# LPC11D14 register map
File version: 4
CPU: 
Registers are 32-bit, read-write, reset 0x0 unless marked. A register's access mark holds for its fields unless they carry their own. Offsets are from the block's base; [hi:lo] are bit positions; {n}, {i} and the like mark numbered series.

## SYSCON — System configuration
Base 0x40048000
0x00 SYSMEMREMAP reset 0x2 — System memory remap
  [1:0] MAP
    0=BOOT_LOADER_MODE_IN (Boot Loader Mode. Interrupt vectors are re-mapped to Boot ROM.); 1=USER_RAM_MODE_INTER (User RAM Mode. Interrupt vectors are re-mapped to Static RAM.); 2=USER_FLASH_MODE_INT (User Flash Mode. Interrupt vectors are not re-mapped and reside in Flash.)
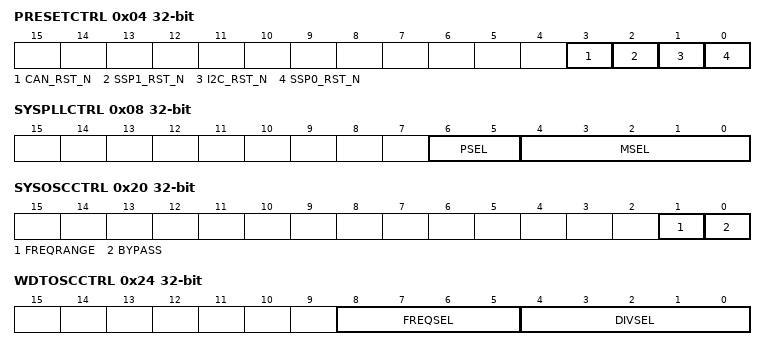
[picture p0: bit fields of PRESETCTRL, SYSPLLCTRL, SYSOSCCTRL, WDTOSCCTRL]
0x04 PRESETCTRL — Peripheral reset control
  [3] CAN_RST_N — C_CAN reset control. See Section 3.1 for part specific details.
    0=RESETS_THE_C_CAN_PER (Resets the C_CAN peripheral.); 1=C_CAN_RESET_DE_ASSER (C_CAN reset de-asserted.)
  [2] SSP1_RST_N — SPI1 reset control
    0=RESETS_THE_SPI1_PERI (Resets the SPI1 peripheral.); 1=SPI1_RESET_DE_ASSERT (SPI1 reset de-asserted.)
  [1] I2C_RST_N — I2C reset control
    0=RESETS_THE_I2C_PERIP (Resets the I2C peripheral.); 1=I2C_RESET_DE_ASSERTE (I2C reset de-asserted.)
  [0] SSP0_RST_N — SPI0 reset control
    0=RESETS_THE_SPI0_PERI (Resets the SPI0 peripheral.); 1=SPI0_RESET_DE_ASSERT (SPI0 reset de-asserted.)
0x08 SYSPLLCTRL — System PLL control
  [6:5] PSEL — Post divider ratio P. The division ratio is 2 x P.
    0=P_EQ_1 (P = 1); 1=P_EQ_2 (P = 2); 2=P_EQ_4 (P = 4); 3=P_EQ_8 (P = 8)
  [4:0] MSEL — Feedback divider value. The division value M is the programmed MSEL value + 1. 00000: Division ratio M = 1 to 11111: Division ratio M = 32.
0x0C SYSPLLSTAT ro — System PLL status
  [0] LOCK — PLL lock status
    0=PLL_NOT_LOCKED; 1=PLL_LOCKED
0x20 SYSOSCCTRL — System oscillator control
  [1] FREQRANGE — Determines frequency range for Low-power oscillator.
    0=1__20_MHZ_FREQUENCY (1 - 20 MHz frequency range.); 1=15__25_MHZ_FREQUENC (15 - 25 MHz frequency range)
  [0] BYPASS — Bypass system oscillator
    0=OSCILLATOR_IS_NOT_BY (Oscillator is not bypassed.); 1=BYPASS_ENABLED_PLL_ (Bypass enabled. PLL input (sys_osc_clk) is fed directly from the XTALIN and XTALOUT pins.)
0x24 WDTOSCCTRL — Watchdog oscillator control
  [8:5] FREQSEL — Select watchdog oscillator analog output frequency (Fclkana).
    1=0_5_MHZ; 2=0_8_MHZ; 3=1_1_MHZ; 4=1_4_MHZ; 5=1_6_MHZ; 6=1_8_MHZ; 7=2_0_MHZ; 8=2_2_MHZ; 9=2_4_MHZ; 10=2_6_MHZ; 11=2_7_MHZ; 12=2_9_MHZ; 13=3_1_MHZ; 14=3_2_MHZ; 15=3_4_MHZ
  [4:0] DIVSEL — Select divider for Fclkana. wdt_osc_clk = Fclkana/ (2 x (1 + DIVSEL)) 00000: 2 x (1 + DIVSEL) = 2 00001: 2 x (1 + DIVSEL) = 4 to 11111: 2 x (1 + DIVSEL) = 64
0x28 IRCCTRL reset 0x80 — IRC control
  [7:0] TRIM — Trim value
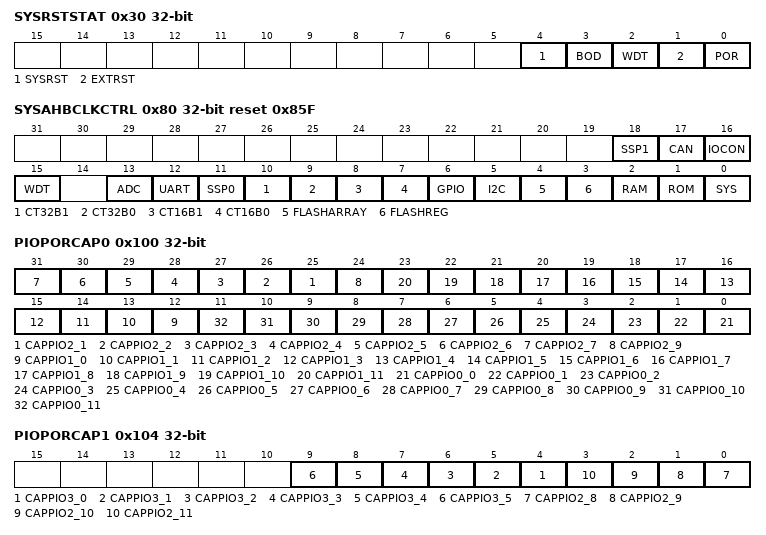
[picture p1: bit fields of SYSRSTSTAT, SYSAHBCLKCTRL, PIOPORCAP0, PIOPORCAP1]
0x30 SYSRSTSTAT ro — System reset status register
  [4] SYSRST — Status of the software system reset
    0=NO_SYSTEM_RESET_DETE (No System reset detected.); 1=SYSTEM_RESET_DETECTE (System reset detected.)
  [3] BOD — Status of the Brown-out detect reset
    0=NO_BOD_RESET_DETECTE (No BOD reset detected.); 1=BOD_RESET_DETECTED_
  [2] WDT — Status of the Watchdog reset
    0=NO_WDT_RESET_DETECTE (No WDT reset detected.); 1=WDT_RESET_DETECTED_
  [1] EXTRST — External RESET status
    0=NO_RESET_EVENT_DETEC (No RESET event detected.); 1=RESET_DETECTED_
  [0] POR — POR reset status
    0=NO_POR_DETECTED_; 1=POR_DETECTED_
0x40 SYSPLLCLKSEL — System PLL clock source select
  [1:0] SEL — System PLL clock source
    0=IRC_OSCILLATOR; 1=SYSTEM_OSCILLATOR
0x44 SYSPLLCLKUEN — System PLL clock source update enable
  [0] ENA — Enable system PLL clock source update
    0=NO_CHANGE; 1=UPDATE_CLOCK_SOURCE
0x70 MAINCLKSEL — Main clock source select
  [1:0] SEL — Clock source for main clock
    0=IRC_OSCILLATOR; 1=INPUT_CLOCK_TO_SYSTE (Input clock to system PLL); 2=WDT_OSCILLATOR; 3=SYSTEM_PLL_CLOCK_OUT
0x74 MAINCLKUEN — Main clock source update enable
  [0] ENA — Enable main clock source update
    0=NO_CHANGE; 1=UPDATE_CLOCK_SOURCE
0x78 SYSAHBCLKDIV reset 0x1 — System AHB clock divider
  [7:0] DIV — System AHB clock divider values 0: System clock disabled. 1: Divide by 1. to 255: Divide by 255.
0x80 SYSAHBCLKCTRL reset 0x85F — System AHB clock control
  [18] SSP1 — Enables clock for SPI1.
    0=DISABLE; 1=ENABLE
  [17] CAN — Enables clock for C_CAN. See Section 3.1 for part specific details.
    0=DISABLE; 1=ENABLE
  [16] IOCON — Enables clock for I/O configuration block.
    0=DISABLE; 1=ENABLE
  [15] WDT — Enables clock for WDT.
    0=DISABLE; 1=ENABLE
  [13] ADC — Enables clock for ADC.
    0=DISABLE; 1=ENABLE
  [12] UART — Enables clock for UART. See Section 3.1 for part specific details.
    0=DISABLE; 1=ENABLE
  [11] SSP0 — Enables clock for SPI0.
    0=DISABLE; 1=ENABLE
  [10] CT32B1 — Enables clock for 32-bit counter/timer 1.
    0=DISABLE; 1=ENABLE
  [9] CT32B0 — Enables clock for 32-bit counter/timer 0.
    0=DISABLE; 1=ENABLE
  [8] CT16B1 — Enables clock for 16-bit counter/timer 1.
    0=DISABLE; 1=ENABLE
  [7] CT16B0 — Enables clock for 16-bit counter/timer 0.
    0=DISABLE; 1=ENABLE
  [6] GPIO — Enables clock for GPIO.
    0=DISABLE; 1=ENABLE
  [5] I2C — Enables clock for I2C.
    0=DISABLE; 1=ENABLE
  [4] FLASHARRAY — Enables clock for flash array access.
    0=DISABLED; 1=ENABLED
  [3] FLASHREG — Enables clock for flash register interface.
    0=DISABLED; 1=ENABLED
  [2] RAM — Enables clock for RAM.
    0=DISABLE; 1=ENABLE
  [1] ROM — Enables clock for ROM.
    0=DISABLE; 1=ENABLE
  [0] SYS — Enables clock for AHB to APB bridge, to the AHB matrix, to the Cortex-M0 FCLK and HCLK, to the SysCon, and to the PMU. This bit is read only.
    1=ENABLE
0x94 SSP0CLKDIV — SPI0 clock divider
  [7:0] DIV — SPI0_PCLK clock divider values 0: Disable SPI0_PCLK. 1: Divide by 1. to 255: Divide by 255.
0x98 UARTCLKDIV — UART clock divder
  [7:0] DIV — UART_PCLK clock divider values 0: Disable UART_PCLK. 1: Divide by 1. to 255: Divide by 255.
0x9C SSP1CLKDIV — SPI1 clock divder
  [7:0] DIV — SPI1_PCLK clock divider values 0: Disable SPI1_PCLK. 1: Divide by 1. to 255: Divide by 255.
0xD0 WDTCLKSEL — WDT clock source select
  [1:0] SEL — WDT clock source
    0=IRC_OSCILLATOR; 1=MAIN_CLOCK; 2=WATCHDOG_OSCILLATOR
0xD4 WDTCLKUEN — WDT clock source update enable
  [0] ENA — Enable WDT clock source update
    0=NO_CHANGE; 1=UPDATE_CLOCK_SOURCE
0xD8 WDTCLKDIV — WDT clock divider
  [7:0] DIV — WDT clock divider values 0: Disable WDCLK. 1: Divide by 1. to 255: Divide by 255.
0xE0 CLKOUTCLKSEL — CLKOUT clock source select
  [1:0] SEL — CLKOUT clock source
    0=IRC_OSCILLATOR; 1=SYSTEM_OSCILLATOR; 2=WATCHDOG_OSCILLATOR; 3=MAIN_CLOCK
0xE4 CLKOUTUEN — CLKOUT clock source update enable
  [0] ENA — Enable CLKOUT clock source update
    0=NO_CHANGE; 1=UPDATE_CLOCK_SOURCE
0xE8 CLKOUTCLKDIV — CLKOUT clock divider
  [7:0] DIV — Clock output divider values 0: Disable CLKOUT. 1: Divide by 1. to 255: Divide by 255.
0x100 PIOPORCAP0 ro reset not defined — POR captured PIO status 0
  [n+24] CAPPIO2_{n} (n=1..7) — Raw reset status input PIO2_n: PIO2_7 to PIO2_0
  [24] CAPPIO2_9 — Raw reset status input PIO2_n: PIO2_7 to PIO2_0
  [n+12] CAPPIO1_{n} (n=0..11) — Raw reset status input PIO1_n: PIO1_11 to PIO1_0
  [n] CAPPIO0_{n} (n=0..11) — Raw reset status input PIO0_n: PIO0_11 to PIO0_0
0x104 PIOPORCAP1 ro reset not defined — POR captured PIO status 1
  [n+4] CAPPIO3_{n} (n=0..5) — Raw reset status input PIO3_{n}
  [n-8] CAPPIO2_{n} (n=8..11) — Raw reset status input PIO2_{n}
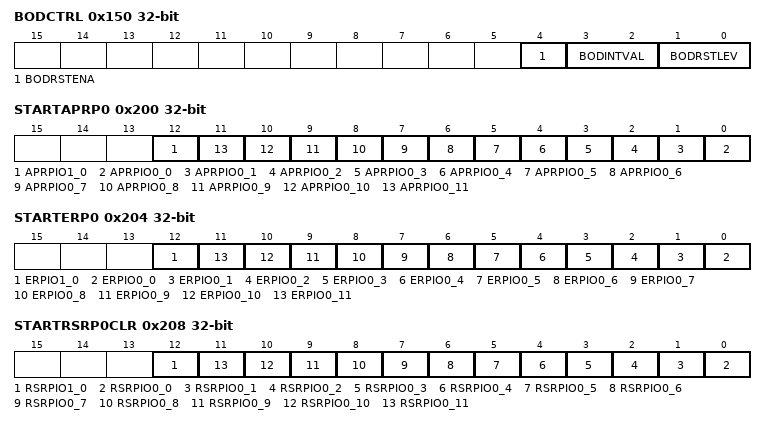
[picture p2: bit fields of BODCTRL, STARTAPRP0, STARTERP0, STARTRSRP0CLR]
0x150 BODCTRL — BOD control
  [4] BODRSTENA — BOD reset enable
    0=DISABLE_RESET_FUNCTI (Disable reset function.); 1=ENABLE_RESET_FUNCTIO (Enable reset function.)
  [3:2] BODINTVAL — BOD interrupt level
    0=LEVEL_0_THE_INTERRU (Level 0: The interrupt assertion threshold voltage is 1.65 V; the interrupt de-assertion threshold voltage is 1.80 V.); 1=LEVEL_1THE_INTERRUP (Level 1:The interrupt assertion threshold voltage is 2.22 V; the interrupt de-assertion threshold voltage is 2.35 V.); 2=LEVEL_2_THE_INTERRU (Level 2: The interrupt assertion threshold voltage is 2.52 V; the interrupt de-assertion threshold voltage is 2.66 V.); 3=LEVEL_3_THE_INTERRU (Level 3: The interrupt assertion threshold voltage is 2.80 V; the interrupt de-assertion threshold voltage is 2.90 V.)
  [1:0] BODRSTLEV — BOD reset level
    0=LEVEL_0_THE_RESET_A (Level 0: The reset assertion threshold voltage is 1.46 V; the reset de-assertion threshold voltage is 1.63 V.); 1=LEVEL_1_THE_RESET_A (Level 1: The reset assertion threshold voltage is 2.06 V; the reset de-assertion threshold voltage is 2.15 V.); 2=LEVEL_2_THE_RESET_A (Level 2: The reset assertion threshold voltage is 2.35 V; the reset de-assertion threshold voltage is 2.43 V.); 3=LEVEL_3_THE_RESET_A (Level 3: The reset assertion threshold voltage is 2.63 V; the reset de-assertion threshold voltage is 2.71 V.)
0x154 SYSTCKCAL reset 0x4 — System tick counter calibration
  [25:0] CAL — System tick timer calibration value
0x200 STARTAPRP0 reset not defined — Start logic edge control register 0
  [12] APRPIO1_0 — Edge select for start logic input PIO1_0 0 = Falling edge 1 = Rising edge
  [n] APRPIO0_{n} (n=0..11) — Edge select for start logic input PIO0_n: PIO0_11 to PIO0_0 0 = Falling edge 1 = Rising edge
0x204 STARTERP0 reset not defined — Start logic signal enable register 0
  [12] ERPIO1_0 — Enable start signal for start logic input PIO1_0 0 = Disabled 1 = Enabled
  [n] ERPIO0_{n} (n=0..11) — Enable start signal for start logic input PIO0_n: PIO0_11 to PIO0_0 0 = Disabled 1 = Enabled
0x208 STARTRSRP0CLR wo reset not defined — Start logic reset register 0
  [12] RSRPIO1_0 — Start signal reset for start logic input PIO1_0 0 = Do nothing. 1 = Writing 1 resets the start signal.
  [n] RSRPIO0_{n} (n=0..11) — Start signal reset for start logic input PIO0_n:PIO0_11 to PIO0_0 0 = Do nothing. 1 = Writing 1 resets the start signal.
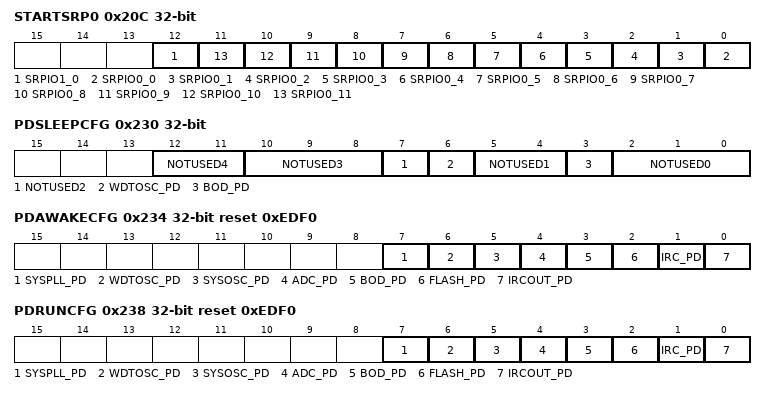
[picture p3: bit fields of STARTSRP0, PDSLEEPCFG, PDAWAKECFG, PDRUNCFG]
0x20C STARTSRP0 ro reset not defined — Start logic status register 0
  [12] SRPIO1_0 — Start signal status for start logic input PIO1_0 0 = No start signal received. 1 = Start signal pending.
  [n] SRPIO0_{n} (n=0..11) — Start signal status for start logic input PIO0_n: PIO0_11 to PIO0_0 0 = No start signal received. 1 = Start signal pending.
0x230 PDSLEEPCFG — Power-down states in Deep-sleep mode
  [12:11] NOTUSED4 — Reserved. Always write these bits as 11.
  [10:8] NOTUSED3 — Reserved. Always write these bits as 000.
  [7] NOTUSED2 — Reserved. Always write this bit as 1.
  [6] WDTOSC_PD — Watchdog oscillator power control in Deep-sleep mode, see Table 39.
    0=POWERED; 1=POWERED_DOWN
  [5:4] NOTUSED1 — Reserved. Always write these bits as 11.
  [3] BOD_PD — BOD power-down control in Deep-sleep mode, see Table 39.
    0=POWERED; 1=POWERED_DOWN
  [2:0] NOTUSED0 — Reserved. Always write these bits as 111.
0x234 PDAWAKECFG reset 0xEDF0 — Power-down states after wake-up from Deep-sleep mode
  [all] fields
    0=POWERED; 1=POWERED_DOWN
  [7] SYSPLL_PD — System PLL wake-up configuration
  [6] WDTOSC_PD — Watchdog oscillator wake-up configuration
  [5] SYSOSC_PD — System oscillator wake-up configuration
  [4] ADC_PD — ADC wake-up configuration
  [3] BOD_PD — BOD wake-up configuration
  [2] FLASH_PD — Flash wake-up configuration
  [1] IRC_PD — IRC oscillator power-down wake-up configuration
  [0] IRCOUT_PD — IRC oscillator output wake-up configuration
0x238 PDRUNCFG reset 0xEDF0 — Power-down configuration register
  [all] fields
    0=POWERED; 1=POWERED_DOWN
  [7] SYSPLL_PD — System PLL power-down
  [6] WDTOSC_PD — Watchdog oscillator power-down
  [5] SYSOSC_PD — System oscillator power-down
  [4] ADC_PD — ADC power-down
  [3] BOD_PD — BOD power-down
  [2] FLASH_PD — Flash power-down
  [1] IRC_PD — IRC oscillator power-down
  [0] IRCOUT_PD — IRC oscillator output power-down
0x3F4 DEVICE_ID ro reset not defined
  [31:0] DEVICEID — Part ID numbers for LPC11D14 0x2540 102B = LPC11D14FBD100/302
